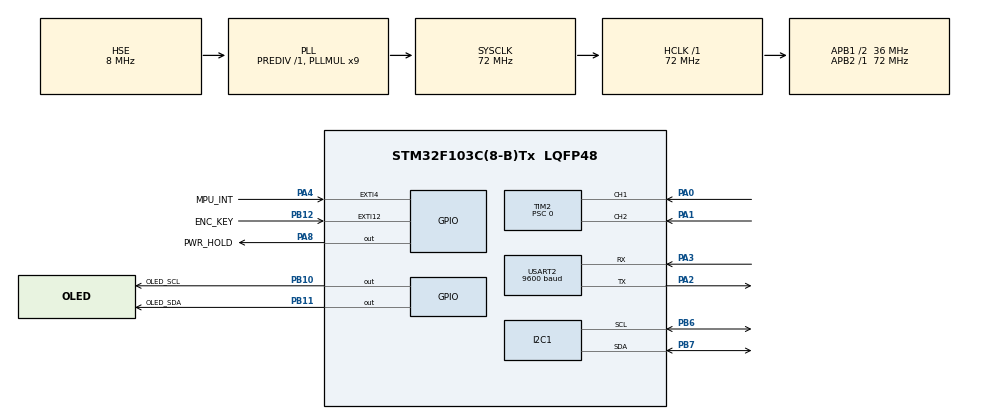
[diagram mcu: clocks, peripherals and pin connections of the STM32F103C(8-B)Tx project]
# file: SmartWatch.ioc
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FREERTOS.HEAP_NUMBER=4
FREERTOS.MEMORY_ALLOCATION=1
FREERTOS.Tasks01=defaultTask,24,128,StartDefaultTask,Default,NULL,Dynamic,NULL,NULL
FREERTOS.configMINIMAL_STACK_SIZE=128
FREERTOS.configTOTAL_HEAP_SIZE=8192
FREERTOS.configUSE_COUNTING_SEMAPHORES=1
FREERTOS.configUSE_MUTEXES=1
FREERTOS.configUSE_PREEMPTION=1
Mcu.Family=STM32F1
Mcu.Name=STM32F103C(8-B)Tx
Mcu.Package=LQFP48
NVIC.EXTI15_10_IRQn=true\:5\:0\:false\:false\:true\:true\:false\:true\:true
NVIC.EXTI4_IRQn=true\:5\:0\:false\:false\:true\:true\:false\:true\:true
NVIC.PriorityGroup=NVIC_PRIORITYGROUP_4
NVIC.TIM4_IRQn=true\:15\:0\:false\:false\:true\:false\:true\:true\:true
NVIC.TimeBase=TIM4_IRQn
NVIC.TimeBaseIP=TIM4
NVIC.USART2_IRQn=true\:5\:0\:false\:false\:true\:true\:false\:true\:true
PA0-WKUP.Signal=S_TIM2_CH1_ETR
PA1.Signal=S_TIM2_CH2
PA13.Mode=Serial_Wire
PA13.Signal=SYS_JTMS-SWDIO
PA14.Mode=Serial_Wire
PA14.Signal=SYS_JTCK-SWCLK
PA2.Mode=Asynchronous
PA2.Signal=USART2_TX
PA3.Mode=Asynchronous
PA3.Signal=USART2_RX
PA4.GPIO_Label=MPU_INT
PA4.GPIO_ModeDefaultEXTI=GPIO_MODE_IT_RISING
PA4.GPIO_PuPd=GPIO_PULLDOWN
PA4.Signal=GPXTI4
PA8.GPIO_Label=PWR_HOLD
PA8.PinState=GPIO_PIN_SET
PA8.Signal=GPIO_Output
PB10.GPIO_Label=OLED_SCL
PB10.Signal=GPIO_Output
PB11.GPIO_Label=OLED_SDA
PB11.Signal=GPIO_Output
PB12.GPIO_Label=ENC_KEY
PB12.GPIO_ModeDefaultEXTI=GPIO_MODE_IT_FALLING
PB12.GPIO_PuPd=GPIO_PULLUP
PB12.Signal=GPXTI12
PB6.Mode=I2C
PB6.Signal=I2C1_SCL
PB7.Mode=I2C
PB7.Signal=I2C1_SDA
PC14-OSC32_IN.Mode=LSE-External-Oscillator
PC14-OSC32_IN.Signal=RCC_OSC32_IN
PC15-OSC32_OUT.Mode=LSE-External-Oscillator
PC15-OSC32_OUT.Signal=RCC_OSC32_OUT
PD0-OSC_IN.Mode=HSE-External-Oscillator
PD0-OSC_IN.Signal=RCC_OSC_IN
PD1-OSC_OUT.Mode=HSE-External-Oscillator
PD1-OSC_OUT.Signal=RCC_OSC_OUT
ProjectManager.HeapSize=0x200
ProjectManager.StackSize=0x400
ProjectManager.TargetToolchain=CMake
RCC.AHBFreq_Value=72000000
RCC.APB1CLKDivider=RCC_HCLK_DIV2
RCC.APB1Freq_Value=36000000
RCC.APB1TimFreq_Value=72000000
RCC.APB2Freq_Value=72000000
RCC.APB2TimFreq_Value=72000000
RCC.HCLKFreq_Value=72000000
RCC.PLLMUL=RCC_PLL_MUL9
RCC.PLLSourceVirtual=RCC_PLLSOURCE_HSE
RCC.RTCClockSelection=RCC_RTCCLKSOURCE_LSE
RCC.SYSCLKFreq_VALUE=72000000
RCC.SYSCLKSource=RCC_SYSCLKSOURCE_PLLCLK
RCC.USBFreq_Value=72000000
SH.S_TIM2_CH1_ETR.0=TIM2_CH1,Encoder_Interface
SH.S_TIM2_CH2.0=TIM2_CH2,Encoder_Interface
TIM2.EncoderMode=TIM_ENCODERMODE_TI12
TIM2.Period=65535
TIM2.Prescaler=0
USART2.BaudRate=9600
USART2.VirtualMode=VM_ASYNC
VP_FREERTOS_VS_CMSIS_V2.Mode=CMSIS_V2
VP_RTC_VS_RTC_Activate.Mode=RTC_Enabled
VP_RTC_VS_RTC_Calendar.Mode=RTC_Calendar
VP_SYS_VS_tim4.Mode=TIM4
board=custom

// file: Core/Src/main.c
/* USER CODE BEGIN Header */
/**
  ******************************************************************************
  * @file           : main.c
  * @brief          : Main program body
  ******************************************************************************
  * @attention
  *
  * Copyright (c) 2026 STMicroelectronics.
  * All rights reserved.
  *
  * This software is licensed under terms that can be found in the LICENSE file
  * in the root directory of this software component.
  * If no LICENSE file comes with this software, it is provided AS-IS.
  *
  ******************************************************************************
  */
/* USER CODE END Header */
#include "main.h"
#include "cmsis_os.h"

/* USER CODE BEGIN Includes */
#include "app_tasks.h"
/* USER CODE END Includes */

I2C_HandleTypeDef hi2c1;

RTC_HandleTypeDef hrtc;

TIM_HandleTypeDef htim2;

UART_HandleTypeDef huart2;

/* Definitions for defaultTask */
osThreadId_t defaultTaskHandle;
const osThreadAttr_t defaultTask_attributes = {
  .name = "defaultTask",
  .stack_size = 128 * 4,
  .priority = (osPriority_t) osPriorityNormal,
};

void SystemClock_Config(void);
static void MX_GPIO_Init(void);
static void MX_I2C1_Init(void);
static void MX_USART2_UART_Init(void);
static void MX_TIM2_Init(void);
static void MX_RTC_Init(void);
void StartDefaultTask(void *argument);

int main(void)
{

  /* MCU Configuration--------------------------------------------------------*/

  /* Reset of all peripherals, Initializes the Flash interface and the Systick. */
  HAL_Init();

  /* USER CODE BEGIN Init */
  /* 一键开机软自锁：必须在 SystemClock_Config 之前把 PA8 拉高维持供电。
   * LSE 起振等待可长达数秒，若等到 MX_GPIO_Init 才拉高，用户松开电源键
   * 的瞬间系统就掉电（此前全工程无任何地方拉高 PA8，属致命遗漏）。 */
  {
    GPIO_InitTypeDef pwr_hold = {0};
    __HAL_RCC_GPIOA_CLK_ENABLE();
    HAL_GPIO_WritePin(PWR_HOLD_GPIO_Port, PWR_HOLD_Pin, GPIO_PIN_SET);
    pwr_hold.Pin   = PWR_HOLD_Pin;
    pwr_hold.Mode  = GPIO_MODE_OUTPUT_PP;
    pwr_hold.Speed = GPIO_SPEED_FREQ_LOW;
    HAL_GPIO_Init(PWR_HOLD_GPIO_Port, &pwr_hold);
  }
  /* USER CODE END Init */

  /* Configure the system clock */
  SystemClock_Config();

  /* Initialize all configured peripherals */
  MX_GPIO_Init();
  MX_I2C1_Init();
  MX_USART2_UART_Init();
  MX_TIM2_Init();
  MX_RTC_Init();
  /* USER CODE BEGIN 2 */
  App_Init();          /* 初始化 OLED/MPU/编码器/RTC，载入 Flash 步数 */
  /* USER CODE END 2 */

  /* Init scheduler */
  osKernelInitialize();

  /* Create the thread(s) */
  /* creation of defaultTask */
  defaultTaskHandle = osThreadNew(StartDefaultTask, NULL, &defaultTask_attributes);

  /* USER CODE BEGIN RTOS_THREADS */
  App_CreateTasks();   /* 创建互斥锁/信号量与四大任务 */
  /* USER CODE END RTOS_THREADS */

  /* Start scheduler */
  osKernelStart();

  /* We should never get here as control is now taken by the scheduler */

  /* Infinite loop */
  while (1)
  {

  }
}

void SystemClock_Config(void)
{
  RCC_OscInitTypeDef RCC_OscInitStruct = {0};
  RCC_ClkInitTypeDef RCC_ClkInitStruct = {0};
  RCC_PeriphCLKInitTypeDef PeriphClkInit = {0};

  /** Initializes the RCC Oscillators according to the specified parameters
  * in the RCC_OscInitTypeDef structure.
  */
  RCC_OscInitStruct.OscillatorType = RCC_OSCILLATORTYPE_HSE|RCC_OSCILLATORTYPE_LSE;
  RCC_OscInitStruct.HSEState = RCC_HSE_ON;
  RCC_OscInitStruct.HSEPredivValue = RCC_HSE_PREDIV_DIV1;
  RCC_OscInitStruct.LSEState = RCC_LSE_ON;
  RCC_OscInitStruct.HSIState = RCC_HSI_ON;
  RCC_OscInitStruct.PLL.PLLState = RCC_PLL_ON;
  RCC_OscInitStruct.PLL.PLLSource = RCC_PLLSOURCE_HSE;
  RCC_OscInitStruct.PLL.PLLMUL = RCC_PLL_MUL9;
  if (HAL_RCC_OscConfig(&RCC_OscInitStruct) != HAL_OK)
  {
    Error_Handler();
  }

  /** Initializes the CPU, AHB and APB buses clocks
  */
  RCC_ClkInitStruct.ClockType = RCC_CLOCKTYPE_HCLK|RCC_CLOCKTYPE_SYSCLK
                              |RCC_CLOCKTYPE_PCLK1|RCC_CLOCKTYPE_PCLK2;
  RCC_ClkInitStruct.SYSCLKSource = RCC_SYSCLKSOURCE_PLLCLK;
  RCC_ClkInitStruct.AHBCLKDivider = RCC_SYSCLK_DIV1;
  RCC_ClkInitStruct.APB1CLKDivider = RCC_HCLK_DIV2;
  RCC_ClkInitStruct.APB2CLKDivider = RCC_HCLK_DIV1;

  if (HAL_RCC_ClockConfig(&RCC_ClkInitStruct, FLASH_LATENCY_2) != HAL_OK)
  {
    Error_Handler();
  }
  PeriphClkInit.PeriphClockSelection = RCC_PERIPHCLK_RTC;
  PeriphClkInit.RTCClockSelection = RCC_RTCCLKSOURCE_LSE;
  if (HAL_RCCEx_PeriphCLKConfig(&PeriphClkInit) != HAL_OK)
  {
    Error_Handler();
  }
}

static void MX_I2C1_Init(void)
{

  hi2c1.Instance = I2C1;
  hi2c1.Init.ClockSpeed = 100000;
  hi2c1.Init.DutyCycle = I2C_DUTYCYCLE_2;
  hi2c1.Init.OwnAddress1 = 0;
  hi2c1.Init.AddressingMode = I2C_ADDRESSINGMODE_7BIT;
  hi2c1.Init.DualAddressMode = I2C_DUALADDRESS_DISABLE;
  hi2c1.Init.OwnAddress2 = 0;
  hi2c1.Init.GeneralCallMode = I2C_GENERALCALL_DISABLE;
  hi2c1.Init.NoStretchMode = I2C_NOSTRETCH_DISABLE;
  if (HAL_I2C_Init(&hi2c1) != HAL_OK)
  {
    Error_Handler();
  }

}

static void MX_RTC_Init(void)
{

  RTC_TimeTypeDef sTime = {0};
  RTC_DateTypeDef DateToUpdate = {0};

  /** Initialize RTC Only
  */
  hrtc.Instance = RTC;
  hrtc.Init.AsynchPrediv = RTC_AUTO_1_SECOND;
  hrtc.Init.OutPut = RTC_OUTPUTSOURCE_ALARM;
  if (HAL_RTC_Init(&hrtc) != HAL_OK)
  {
    Error_Handler();
  }

  /* USER CODE BEGIN Check_RTC_BKUP */
  /* 若备份寄存器已有初始化魔数，说明 RTC 之前已设过时间且仍在走时，
   * 直接返回、跳过下面的清零，避免每次复位把时间重置为 00:00:00。
   * (注意：面包板无 VBAT 纽扣电池，彻底断电仍会丢时；软复位/看门狗复位不会丢) */
  if (HAL_RTCEx_BKUPRead(&hrtc, RTC_BKP_DR1) == 0x32F2)
  {
    return;
  }
  /* USER CODE END Check_RTC_BKUP */

  /** Initialize RTC and set the Time and Date
  */
  sTime.Hours = 0x0;
  sTime.Minutes = 0x0;
  sTime.Seconds = 0x0;

  if (HAL_RTC_SetTime(&hrtc, &sTime, RTC_FORMAT_BCD) != HAL_OK)
  {
    Error_Handler();
  }
  DateToUpdate.WeekDay = RTC_WEEKDAY_MONDAY;
  DateToUpdate.Month = RTC_MONTH_JANUARY;
  DateToUpdate.Date = 0x1;
  DateToUpdate.Year = 0x0;

  if (HAL_RTC_SetDate(&hrtc, &DateToUpdate, RTC_FORMAT_BCD) != HAL_OK)
  {
    Error_Handler();
  }
  /* USER CODE BEGIN RTC_Init 2 */
  /* 首次初始化完成，打上魔数标记，之后复位不再清零走时 */
  HAL_RTCEx_BKUPWrite(&hrtc, RTC_BKP_DR1, 0x32F2);
  /* USER CODE END RTC_Init 2 */

}

static void MX_TIM2_Init(void)
{

  TIM_Encoder_InitTypeDef sConfig = {0};
  TIM_MasterConfigTypeDef sMasterConfig = {0};

  htim2.Instance = TIM2;
  htim2.Init.Prescaler = 0;
  htim2.Init.CounterMode = TIM_COUNTERMODE_UP;
  htim2.Init.Period = 65535;
  htim2.Init.ClockDivision = TIM_CLOCKDIVISION_DIV1;
  htim2.Init.AutoReloadPreload = TIM_AUTORELOAD_PRELOAD_DISABLE;
  sConfig.EncoderMode = TIM_ENCODERMODE_TI12;
  sConfig.IC1Polarity = TIM_ICPOLARITY_RISING;
  sConfig.IC1Selection = TIM_ICSELECTION_DIRECTTI;
  sConfig.IC1Prescaler = TIM_ICPSC_DIV1;
  sConfig.IC1Filter = 0;
  sConfig.IC2Polarity = TIM_ICPOLARITY_RISING;
  sConfig.IC2Selection = TIM_ICSELECTION_DIRECTTI;
  sConfig.IC2Prescaler = TIM_ICPSC_DIV1;
  sConfig.IC2Filter = 0;
  if (HAL_TIM_Encoder_Init(&htim2, &sConfig) != HAL_OK)
  {
    Error_Handler();
  }
  sMasterConfig.MasterOutputTrigger = TIM_TRGO_RESET;
  sMasterConfig.MasterSlaveMode = TIM_MASTERSLAVEMODE_DISABLE;
  if (HAL_TIMEx_MasterConfigSynchronization(&htim2, &sMasterConfig) != HAL_OK)
  {
    Error_Handler();
  }

}

static void MX_USART2_UART_Init(void)
{

  huart2.Instance = USART2;
  huart2.Init.BaudRate = 9600;
  huart2.Init.WordLength = UART_WORDLENGTH_8B;
  huart2.Init.StopBits = UART_STOPBITS_1;
  huart2.Init.Parity = UART_PARITY_NONE;
  huart2.Init.Mode = UART_MODE_TX_RX;
  huart2.Init.HwFlowCtl = UART_HWCONTROL_NONE;
  huart2.Init.OverSampling = UART_OVERSAMPLING_16;
  if (HAL_UART_Init(&huart2) != HAL_OK)
  {
    Error_Handler();
  }

}

static void MX_GPIO_Init(void)
{
  GPIO_InitTypeDef GPIO_InitStruct = {0};

  /* GPIO Ports Clock Enable */
  __HAL_RCC_GPIOC_CLK_ENABLE();
  __HAL_RCC_GPIOD_CLK_ENABLE();
  __HAL_RCC_GPIOA_CLK_ENABLE();
  __HAL_RCC_GPIOB_CLK_ENABLE();

  /*Configure GPIO pin Output Level */
  HAL_GPIO_WritePin(GPIOB, OLED_SCL_Pin|OLED_SDA_Pin, GPIO_PIN_RESET);

  /*Configure GPIO pin Output Level */
  HAL_GPIO_WritePin(PWR_HOLD_GPIO_Port, PWR_HOLD_Pin, GPIO_PIN_SET);

  /*Configure GPIO pin : MPU_INT_Pin */
  GPIO_InitStruct.Pin = MPU_INT_Pin;
  GPIO_InitStruct.Mode = GPIO_MODE_IT_RISING;
  GPIO_InitStruct.Pull = GPIO_PULLDOWN;
  HAL_GPIO_Init(MPU_INT_GPIO_Port, &GPIO_InitStruct);

  /*Configure GPIO pins : OLED_SCL_Pin OLED_SDA_Pin */
  GPIO_InitStruct.Pin = OLED_SCL_Pin|OLED_SDA_Pin;
  GPIO_InitStruct.Mode = GPIO_MODE_OUTPUT_PP;
  GPIO_InitStruct.Pull = GPIO_NOPULL;
  GPIO_InitStruct.Speed = GPIO_SPEED_FREQ_LOW;
  HAL_GPIO_Init(GPIOB, &GPIO_InitStruct);

  /*Configure GPIO pin : ENC_KEY_Pin */
  GPIO_InitStruct.Pin = ENC_KEY_Pin;
  GPIO_InitStruct.Mode = GPIO_MODE_IT_FALLING;
  GPIO_InitStruct.Pull = GPIO_PULLUP;
  HAL_GPIO_Init(ENC_KEY_GPIO_Port, &GPIO_InitStruct);

  /*Configure GPIO pin : PWR_HOLD_Pin */
  GPIO_InitStruct.Pin = PWR_HOLD_Pin;
  GPIO_InitStruct.Mode = GPIO_MODE_OUTPUT_PP;
  GPIO_InitStruct.Pull = GPIO_NOPULL;
  GPIO_InitStruct.Speed = GPIO_SPEED_FREQ_LOW;
  HAL_GPIO_Init(PWR_HOLD_GPIO_Port, &GPIO_InitStruct);

  /* EXTI interrupt init*/
  HAL_NVIC_SetPriority(EXTI4_IRQn, 5, 0);
  HAL_NVIC_EnableIRQ(EXTI4_IRQn);

  HAL_NVIC_SetPriority(EXTI15_10_IRQn, 5, 0);
  HAL_NVIC_EnableIRQ(EXTI15_10_IRQn);

}

void StartDefaultTask(void *argument)
{
  for(;;)
  {
    osDelay(1);
  }
}

void HAL_TIM_PeriodElapsedCallback(TIM_HandleTypeDef *htim)
{
  if (htim->Instance == TIM4)
  {
    HAL_IncTick();
  }
}

void Error_Handler(void)
{
  __disable_irq();
  while (1)
  {
  }
}
